# LKS32MC03x register map
Vendor: Linko Ltd.; Series: LKS32MC03x; File version: 1.0
ARM 32-bit Cortex-M0 Microcontroller based device, CPU clock up to 48MHz, etc.
CPU: CM0 r1p0, little endian, MPU, no FPU, 3 interrupt priority bits
Registers are 32-bit, read-write, reset 0x0 unless marked. A register's access mark holds for its fields unless they carry their own. Offsets are from the block's base; lines under a group give offsets from that group; [hi:lo] are bit positions; {n}, {i} and the like mark numbered series; 'fields as' and 'values as' point back to an identical list; <NAME> marks a mode.

## Memory map
0x00010000 FLASH size 0x40 — FLASH registers
0x40000000 SYS size 0x100 — SYS registers
0x40010000 SPI size 0x100 — SPI registers
0x40010100 I2C size 0x100 — I2C registers
0x40010200 CMP size 0x100 — CMP registers
0x40010300 HALL size 0x100 — HALL registers
0x40010400 ADC size 0x100 — ADC registers
0x40010500 UTIMER0 size 0x24 — 16-bit UTIMER0 registers
0x40010600 UTIMER1 size 0x24 — 32-bit UTIMER1 registers
0x40010700 MCPWM size 0x100 — MCPWM registers
0x40010800 GPIO0 size 0x40 — GPIO0 registers
0x40010840 GPIO1 size 0x40 — GPIO1 registers
0x40010880 EXTI size 0x40 — EXTI registers
0x40010900 UART size 0x100 — UART registers
0x40010A00 DMA size 0x100 — DMA registers
0x40010B00 DSP size 0x100 — DSP registers
0x40010C00 IWDG size 0x20 — IWDG registers
0x40010C20 AON size 0x10 — AON registers

## Interrupts
0 TIMER0 (UTIMER0)
1 TIMER1 (UTIMER1)
2 MCPWM0 (MCPWM)
3 MCPWM1 (MCPWM)
4 I2C
5 SPI
6 GPIO (EXTI) — GPIO interrupt
7 HALL
8 UART
9 CMP
10 ADC
11 DMA
12 WAKE (SYS)
13 SW (SYS)

## FLASH — FLASH registers
Base 0x00010000
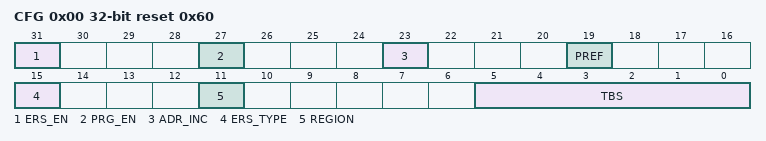
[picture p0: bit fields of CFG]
0x00 CFG reset 0x60 — Flash Configure Register
  [31] ERS_EN — Flash erase operation enable
    0=DISABLED (Erase is disabled); 1=ENABLED (Erase is enabled)
  [27] PRG_EN — Flash program operation is enabled or not
    0=DISABLED (Program is disabled); 1=ENABLED (Program is enabled)
  [23] ADR_INC — Flash address is incremented automatically or not during sequent access
    0=DISABLED (Address incrementation is disabled); 1=ENABLED (Address incrementation is enabled)
  [19] PREF — Prefetch Function Enable or Disable
    0=DISABLED (Prefetch is disabled); 1=ENABLED (Prefetch is enabled)
  [15] ERS_TYPE — Erase Type: Sector/Full
    0=SECTOR (Sector erase); 1=CHIP (Full chip erase)
  [11] REGION — Access Main or NVR
    0=MAIN (Main access); 1=NVR (NVR access)
  [5:0] TBS — Program/Erase timer baseline
    48=48MHz (Program/Erase Timer value @ 48Mhz); 23=24MHz (Program/Erase Timer value @ 24Mhz); 11=12MHz (Program/Erase Timer value @ 12Mhz)
0x04 ADDR — Flash Access Address Register
0x08 WDATA wo — Flash Write Data Register
0x0C RDATA ro — Flash Read Data Register
0x10 ERASE wo — Flash Register Trig Erase Operation(Write 0x7654DCBA to Trig Erase Operation)
0x14 PROTECT ro — Read to update Flash Protection Status
0x18 READY ro (reset mask 0x80000000) — Flash Busy/Idle Status

## SPI — SPI registers
Base 0x40010000
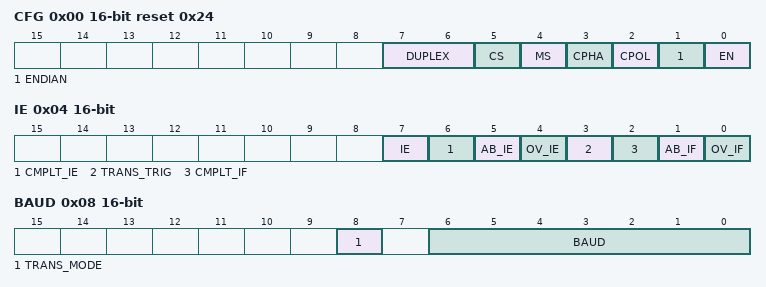
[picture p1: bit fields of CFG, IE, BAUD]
0x00 CFG 16-bit reset 0x24 — SPI Control Register
  [7:6] DUPLEX — Half duplex config
    3=DuplexRx (Half duplex with Rx only); 2=DuplexTx (Half duplex with Tx only); 1=NoDuplex2; 0=NoDuplex
  [5] CS — SPI chip select control big
    0=Always0 (if in spi slave mode, always selected); 1=FromMaster (if in spi slave mode, SPI_CS signal is from spi master)
  [4] MS — SPI device is master or slave
    0=SLAVE (slave mode); 1=MASTER (master mode)
  [3] CPHA — Clock phase
    0=PRNT (positive clock edge sample data, negative clock edge send data); 1=PTNR (positive clock edge send data, negative clock edge sample data)
  [2] CPOL — Clock polarity
    0=LOW (clock default value is low); 1=HIGH (clock default value is high)
  [1] ENDIAN — SPI data endianness
    0=BIG (big endian mode, most significant bit sent first); 1=LITTLE (little endian mode, least significant bit sent first)
  [0] EN — SPI module enable
    0=DISABLED (disable spi module); 1=ENABLED (enable spi module)
0x04 IE 16-bit — SPI Interrupt Register
  [7] IE — Interrupt Enable
    0=DISABLED (SPI interrupt is disabled); 1=ENABLED (SPI interrupt is enabled)
  [6] CMPLT_IE — Transfer Complete Interrupt Enable
    0=DISABLED (SPI transfer complete interrupt is disabled); 1=ENABLED (SPI transfer complete interrupt is enabled)
  [5] AB_IE — Abnormal Interrupt Enable
    0=DISABLED (SPI abnormal interrupt is disabled); 1=ENABLED (SPI abnormal interrupt is enabled)
  [4] OV_IE — Overflow Interrupt Enable
    0=DISABLED (SPI overflow interrupt is disabled); 1=ENABLED (SPI overflow interrupt is enabled)
  [3] TRANS_TRIG — Trigger Source
    0=Internal (Trigger comes from internal source. Only active in master mode); 1=External (Trigger comes from external source)
  [2] CMPLT_IF — Transfer Complete Interrupt
    0=CLEAR (SPI transfer complete interrupt is cleared); 1=SET (SPI transfer complete interrupt is set)
  [1] AB_IF — Abnormal Interrupt
    0=CLEAR (SPI abnormal interrupt is cleared); 1=SET (SPI abnormal interrupt is set)
  [0] OV_IF — Overflow Interrupt
    0=CLEAR (SPI overflow interrupt is cleared); 1=SET (SPI overflow interrupt is set)
0x08 BAUD 16-bit — SPI Buadrate
  [8] TRANS_MODE — by DMA or CPU
    0=DMA (Transfer by DMA); 1=CPU (Transfer by CPU)
  [6:0] BAUD — SPI baudrate = sys_clk/(2*BAUD+1) BAUD should be larger than 3
0x0C TXDATA 16-bit — SPI Tx Data
0x10 RXDATA 16-bit — SPI Rx Data
0x14 SIZE 16-bit — SPI Data length in bits
  [4:0] BITSIZE — Data length
    {v}={v}BIT ({v}bit per byte) (v=8..16)

## Licence text in the file
ARM Limited (ARM) is supplying this software for use with Cortex-M processor based microcontroller, but can be equally used for other suitable processor architectures. This file can be freely distributed. Modifications to this file shall be clearly marked. . THIS SOFTWARE IS PROVIDED "AS IS". NO WARRANTIES, WHETHER EXPRESS, IMPLIED. OR STATUTORY, INCLUDING, BUT NOT LIMITED TO, IMPLIED WARRANTIES OF. MERCHANTABILITY AND FITNESS FOR A PARTICULAR PURPOSE APPLY TO THIS SOFTWARE. ARM SHALL NOT, IN ANY CIRCUMSTANCES, BE LIABLE FOR SPECIAL, INCIDENTAL, OR. CONSEQUENTIAL DAMAGES, FOR ANY REASON WHATSOEVER.

## Notices in the file
Copyright (C) 2012-2014 ARM Limited. All rights reserved.
Purpose: System Viewer Description (SVD) Example (Schema Version 1.1)
This is a description of a none-existent and incomplete device
for demonstration purposes only.
Redistribution and use in source and binary forms, with or without
modification, are permitted provided that the following conditions are met:
- Redistributions of source code must retain the above copyright
notice, this list of conditions and the following disclaimer.
- Redistributions in binary form must reproduce the above copyright
notice, this list of conditions and the following disclaimer in the
documentation and/or other materials provided with the distribution.
- Neither the name of ARM nor the names of its contributors may be used
to endorse or promote products derived from this software without
specific prior written permission.
THIS SOFTWARE IS PROVIDED BY THE COPYRIGHT HOLDERS AND CONTRIBUTORS "AS IS"
AND ANY EXPRESS OR IMPLIED WARRANTIES, INCLUDING, BUT NOT LIMITED TO, THE
ARE DISCLAIMED. IN NO EVENT SHALL COPYRIGHT HOLDERS AND CONTRIBUTORS BE
LIABLE FOR ANY DIRECT, INDIRECT, INCIDENTAL, SPECIAL, EXEMPLARY, OR
CONSEQUENTIAL DAMAGES (INCLUDING, BUT NOT LIMITED TO, PROCUREMENT OF
SUBSTITUTE GOODS OR SERVICES; LOSS OF USE, DATA, OR PROFITS; OR BUSINESS
INTERRUPTION) HOWEVER CAUSED AND ON ANY THEORY OF LIABILITY, WHETHER IN
CONTRACT, STRICT LIABILITY, OR TORT (INCLUDING NEGLIGENCE OR OTHERWISE)
ARISING IN ANY WAY OUT OF THE USE OF THIS SOFTWARE, EVEN IF ADVISED OF THE
POSSIBILITY OF SUCH DAMAGE.
